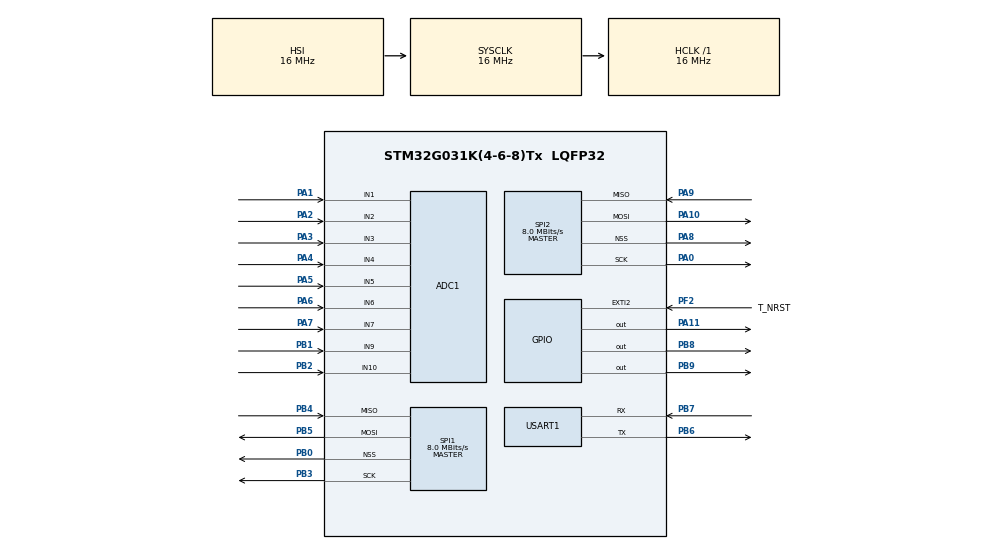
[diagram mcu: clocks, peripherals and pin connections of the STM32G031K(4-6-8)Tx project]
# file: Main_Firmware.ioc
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ADC1.Channel-0\#ChannelRegularConversion=ADC_CHANNEL_4
ADC1.NbrOfConversionFlag=1
ADC1.Rank-0\#ChannelRegularConversion=1
ADC1.SamplingTime-0\#ChannelRegularConversion=ADC_SAMPLINGTIME_COMMON_1
ADC1.SelectedChannel=ADC_CHANNEL_1|ADC_CHANNEL_2|ADC_CHANNEL_3|ADC_CHANNEL_4|ADC_CHANNEL_5|ADC_CHANNEL_6|ADC_CHANNEL_7|ADC_CHANNEL_9|ADC_CHANNEL_10
ADC1.master=1
Mcu.Family=STM32G0
Mcu.Name=STM32G031K(4-6-8)Tx
Mcu.Package=LQFP32
PA0.Mode=Full_Duplex_Master
PA0.Signal=SPI2_SCK
PA1.Mode=IN1
PA1.Signal=ADC1_IN1
PA10.Mode=Full_Duplex_Master
PA10.Signal=SPI2_MOSI
PA11\ [PA9].Signal=GPIO_Output
PA13.GPIO_Label=T_JTMS
PA13.Mode=Serial_Wire
PA13.Signal=SYS_SWDIO
PA14-BOOT0.GPIO_Label=T_JTCK
PA14-BOOT0.Mode=Serial_Wire
PA14-BOOT0.Signal=SYS_SWCLK
PA2.Mode=IN2
PA2.Signal=ADC1_IN2
PA3.Mode=IN3
PA3.Signal=ADC1_IN3
PA4.Mode=IN4
PA4.Signal=ADC1_IN4
PA5.Mode=IN5
PA5.Signal=ADC1_IN5
PA6.Mode=IN6
PA6.Signal=ADC1_IN6
PA7.Mode=IN7
PA7.Signal=ADC1_IN7
PA8.Mode=NSS_Signal_Hard_Output
PA8.Signal=SPI2_NSS
PA9.Mode=Full_Duplex_Master
PA9.Signal=SPI2_MISO
PB0.Mode=NSS_Signal_Hard_Output
PB0.Signal=SPI1_NSS
PB1.Mode=IN9
PB1.Signal=ADC1_IN9
PB2.Mode=IN10
PB2.Signal=ADC1_IN10
PB3.Mode=Full_Duplex_Master
PB3.Signal=SPI1_SCK
PB4.Mode=Full_Duplex_Master
PB4.Signal=SPI1_MISO
PB5.Mode=Full_Duplex_Master
PB5.Signal=SPI1_MOSI
PB6.Mode=Asynchronous
PB6.Signal=USART1_TX
PB7.Mode=Asynchronous
PB7.Signal=USART1_RX
PB8.Signal=GPIO_Output
PB9.Signal=GPIO_Output
PC14-OSC32_IN\ (PC14).Mode=LSE-External-Oscillator
PC14-OSC32_IN\ (PC14).Signal=RCC_OSC32_IN
PC15-OSC32_OUT\ (PC15).Mode=LSE-External-Oscillator
PC15-OSC32_OUT\ (PC15).Signal=RCC_OSC32_OUT
PF2\ -\ NRST.GPIO_Label=T_NRST
PF2\ -\ NRST.Signal=GPXTI2
ProjectManager.HeapSize=0x200
ProjectManager.StackSize=0x400
ProjectManager.TargetToolchain=STM32CubeIDE
RCC.AHBFreq_Value=16000000
RCC.CortexFreq_Value=16000000
RCC.EXTERNAL_CLOCK_VALUE=12288000
RCC.HCLKFreq_Value=16000000
RCC.HSE_VALUE=8000000
RCC.HSI_VALUE=16000000
RCC.SYSCLKFreq_VALUE=16000000
RCC.VCOOutputFreq_Value=128000000
SPI1.CalculateBaudRate=8.0 MBits/s
SPI1.Direction=SPI_DIRECTION_2LINES
SPI1.Mode=SPI_MODE_MASTER
SPI1.VirtualNSS=VM_NSSHARD
SPI1.VirtualType=VM_MASTER
SPI2.CalculateBaudRate=8.0 MBits/s
SPI2.Direction=SPI_DIRECTION_2LINES
SPI2.Mode=SPI_MODE_MASTER
SPI2.VirtualNSS=VM_NSSHARD
SPI2.VirtualType=VM_MASTER
USART1.VirtualMode-Asynchronous=VM_ASYNC
board=NUCLEO-G031K8

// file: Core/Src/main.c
/* USER CODE BEGIN Header */
/**
  ******************************************************************************
  * @file           : main.c
  * @brief          : Main program body
  ******************************************************************************
  * @attention
  *
  * <h2><center>&copy; Copyright (c) 2023 STMicroelectronics.
  * All rights reserved.</center></h2>
  *
  * This software component is licensed by ST under BSD 3-Clause license,
  * the "License"; You may not use this file except in compliance with the
  * License. You may obtain a copy of the License at:
  *                        opensource.org/licenses/BSD-3-Clause
  *
  ******************************************************************************
  */
/* USER CODE END Header */
#include "main.h"
#include "main_loop_controller.h"

ADC_HandleTypeDef hadc1;

SPI_HandleTypeDef hspi1;
SPI_HandleTypeDef hspi2;

UART_HandleTypeDef huart1;

void SystemClock_Config(void);
static void MX_GPIO_Init(void);
static void MX_ADC1_Init(void);
static void MX_SPI2_Init(void);
static void MX_USART1_UART_Init(void);
static void MX_SPI1_Init(void);

int main(void)
{

  /* MCU Configuration--------------------------------------------------------*/

  /* Reset of all peripherals, Initializes the Flash interface and the Systick. */
  HAL_Init();

  /* Configure the system clock */
  SystemClock_Config();

  /* Initialize all configured peripherals */
  MX_GPIO_Init();
  MX_ADC1_Init();
  MX_SPI2_Init();
  MX_USART1_UART_Init();
  MX_SPI1_Init();

  /* USER CODE BEGIN 2 */
  run_once_on_boot();
  /* USER CODE END 2 */

  /* Infinite loop */
  while (1) {
    main_loop();
  }
}

void SystemClock_Config(void)
{
  RCC_OscInitTypeDef RCC_OscInitStruct = {0};
  RCC_ClkInitTypeDef RCC_ClkInitStruct = {0};
  RCC_PeriphCLKInitTypeDef PeriphClkInit = {0};

  /** Configure the main internal regulator output voltage
  */
  HAL_PWREx_ControlVoltageScaling(PWR_REGULATOR_VOLTAGE_SCALE1);
  /** Initializes the RCC Oscillators according to the specified parameters
  * in the RCC_OscInitTypeDef structure.
  */
  RCC_OscInitStruct.OscillatorType = RCC_OSCILLATORTYPE_HSI;
  RCC_OscInitStruct.HSIState = RCC_HSI_ON;
  RCC_OscInitStruct.HSIDiv = RCC_HSI_DIV1;
  RCC_OscInitStruct.HSICalibrationValue = RCC_HSICALIBRATION_DEFAULT;
  RCC_OscInitStruct.PLL.PLLState = RCC_PLL_NONE;
  if (HAL_RCC_OscConfig(&RCC_OscInitStruct) != HAL_OK)
  {
    Error_Handler();
  }
  /** Initializes the CPU, AHB and APB buses clocks
  */
  RCC_ClkInitStruct.ClockType = RCC_CLOCKTYPE_HCLK|RCC_CLOCKTYPE_SYSCLK
                              |RCC_CLOCKTYPE_PCLK1;
  RCC_ClkInitStruct.SYSCLKSource = RCC_SYSCLKSOURCE_HSI;
  RCC_ClkInitStruct.AHBCLKDivider = RCC_SYSCLK_DIV1;
  RCC_ClkInitStruct.APB1CLKDivider = RCC_HCLK_DIV1;

  if (HAL_RCC_ClockConfig(&RCC_ClkInitStruct, FLASH_LATENCY_0) != HAL_OK)
  {
    Error_Handler();
  }
  /** Initializes the peripherals clocks
  */
  PeriphClkInit.PeriphClockSelection = RCC_PERIPHCLK_USART1|RCC_PERIPHCLK_ADC;
  PeriphClkInit.Usart1ClockSelection = RCC_USART1CLKSOURCE_PCLK1;
  PeriphClkInit.AdcClockSelection = RCC_ADCCLKSOURCE_SYSCLK;
  if (HAL_RCCEx_PeriphCLKConfig(&PeriphClkInit) != HAL_OK)
  {
    Error_Handler();
  }
}

static void MX_ADC1_Init(void)
{

  ADC_ChannelConfTypeDef sConfig = {0};

  /** Configure the global features of the ADC (Clock, Resolution, Data Alignment and number of conversion)
  */
  hadc1.Instance = ADC1;
  hadc1.Init.ClockPrescaler = ADC_CLOCK_SYNC_PCLK_DIV2;
  hadc1.Init.Resolution = ADC_RESOLUTION_12B;
  hadc1.Init.DataAlign = ADC_DATAALIGN_RIGHT;
  hadc1.Init.ScanConvMode = ADC_SCAN_DISABLE;
  hadc1.Init.EOCSelection = ADC_EOC_SINGLE_CONV;
  hadc1.Init.LowPowerAutoWait = DISABLE;
  hadc1.Init.LowPowerAutoPowerOff = DISABLE;
  hadc1.Init.ContinuousConvMode = DISABLE;
  hadc1.Init.NbrOfConversion = 1;
  hadc1.Init.DiscontinuousConvMode = DISABLE;
  hadc1.Init.ExternalTrigConv = ADC_SOFTWARE_START;
  hadc1.Init.ExternalTrigConvEdge = ADC_EXTERNALTRIGCONVEDGE_NONE;
  hadc1.Init.DMAContinuousRequests = DISABLE;
  hadc1.Init.Overrun = ADC_OVR_DATA_PRESERVED;
  hadc1.Init.SamplingTimeCommon1 = ADC_SAMPLETIME_1CYCLE_5;
  hadc1.Init.SamplingTimeCommon2 = ADC_SAMPLETIME_1CYCLE_5;
  hadc1.Init.OversamplingMode = DISABLE;
  hadc1.Init.TriggerFrequencyMode = ADC_TRIGGER_FREQ_HIGH;
  if (HAL_ADC_Init(&hadc1) != HAL_OK)
  {
    Error_Handler();
  }
  /** Configure Regular Channel
  */
  sConfig.Channel = ADC_CHANNEL_4;
  sConfig.Rank = ADC_REGULAR_RANK_1;
  sConfig.SamplingTime = ADC_SAMPLINGTIME_COMMON_1;
  if (HAL_ADC_ConfigChannel(&hadc1, &sConfig) != HAL_OK)
  {
    Error_Handler();
  }

}

static void MX_SPI1_Init(void)
{

  /* SPI1 parameter configuration*/
  hspi1.Instance = SPI1;
  hspi1.Init.Mode = SPI_MODE_MASTER;
  hspi1.Init.Direction = SPI_DIRECTION_2LINES;
  hspi1.Init.DataSize = SPI_DATASIZE_8BIT;
  hspi1.Init.CLKPolarity = SPI_POLARITY_LOW;
  hspi1.Init.CLKPhase = SPI_PHASE_1EDGE;
  hspi1.Init.NSS = SPI_NSS_HARD_OUTPUT;
  hspi1.Init.BaudRatePrescaler = SPI_BAUDRATEPRESCALER_2;
  hspi1.Init.FirstBit = SPI_FIRSTBIT_MSB;
  hspi1.Init.TIMode = SPI_TIMODE_DISABLE;
  hspi1.Init.CRCCalculation = SPI_CRCCALCULATION_DISABLE;
  hspi1.Init.CRCPolynomial = 7;
  hspi1.Init.CRCLength = SPI_CRC_LENGTH_DATASIZE;
  hspi1.Init.NSSPMode = SPI_NSS_PULSE_ENABLE;
  if (HAL_SPI_Init(&hspi1) != HAL_OK)
  {
    Error_Handler();
  }

}

static void MX_SPI2_Init(void)
{

  /* SPI2 parameter configuration*/
  hspi2.Instance = SPI2;
  hspi2.Init.Mode = SPI_MODE_MASTER;
  hspi2.Init.Direction = SPI_DIRECTION_2LINES;
  hspi2.Init.DataSize = SPI_DATASIZE_8BIT;
  hspi2.Init.CLKPolarity = SPI_POLARITY_LOW;
  hspi2.Init.CLKPhase = SPI_PHASE_1EDGE;
  hspi2.Init.NSS = SPI_NSS_HARD_OUTPUT;
  hspi2.Init.BaudRatePrescaler = SPI_BAUDRATEPRESCALER_2;
  hspi2.Init.FirstBit = SPI_FIRSTBIT_MSB;
  hspi2.Init.TIMode = SPI_TIMODE_DISABLE;
  hspi2.Init.CRCCalculation = SPI_CRCCALCULATION_DISABLE;
  hspi2.Init.CRCPolynomial = 7;
  hspi2.Init.CRCLength = SPI_CRC_LENGTH_DATASIZE;
  hspi2.Init.NSSPMode = SPI_NSS_PULSE_ENABLE;
  if (HAL_SPI_Init(&hspi2) != HAL_OK)
  {
    Error_Handler();
  }

}

static void MX_USART1_UART_Init(void)
{

  huart1.Instance = USART1;
  huart1.Init.BaudRate = 115200;
  huart1.Init.WordLength = UART_WORDLENGTH_8B;
  huart1.Init.StopBits = UART_STOPBITS_1;
  huart1.Init.Parity = UART_PARITY_NONE;
  huart1.Init.Mode = UART_MODE_TX_RX;
  huart1.Init.HwFlowCtl = UART_HWCONTROL_NONE;
  huart1.Init.OverSampling = UART_OVERSAMPLING_16;
  huart1.Init.OneBitSampling = UART_ONE_BIT_SAMPLE_DISABLE;
  huart1.Init.ClockPrescaler = UART_PRESCALER_DIV1;
  huart1.AdvancedInit.AdvFeatureInit = UART_ADVFEATURE_NO_INIT;
  if (HAL_UART_Init(&huart1) != HAL_OK)
  {
    Error_Handler();
  }
  if (HAL_UARTEx_SetTxFifoThreshold(&huart1, UART_TXFIFO_THRESHOLD_1_8) != HAL_OK)
  {
    Error_Handler();
  }
  if (HAL_UARTEx_SetRxFifoThreshold(&huart1, UART_RXFIFO_THRESHOLD_1_8) != HAL_OK)
  {
    Error_Handler();
  }
  if (HAL_UARTEx_DisableFifoMode(&huart1) != HAL_OK)
  {
    Error_Handler();
  }

}

static void MX_GPIO_Init(void)
{
  GPIO_InitTypeDef GPIO_InitStruct = {0};

  /* GPIO Ports Clock Enable */
  __HAL_RCC_GPIOB_CLK_ENABLE();
  __HAL_RCC_GPIOC_CLK_ENABLE();
  __HAL_RCC_GPIOF_CLK_ENABLE();
  __HAL_RCC_GPIOA_CLK_ENABLE();

  /*Configure GPIO pin Output Level */
  HAL_GPIO_WritePin(GPIOB, GPIO_PIN_9|GPIO_PIN_8, GPIO_PIN_RESET);

  /*Configure GPIO pin Output Level */
  HAL_GPIO_WritePin(GPIOA, GPIO_PIN_11, GPIO_PIN_RESET);

  /*Configure GPIO pins : PB9 PB8 */
  GPIO_InitStruct.Pin = GPIO_PIN_9|GPIO_PIN_8;
  GPIO_InitStruct.Mode = GPIO_MODE_OUTPUT_PP;
  GPIO_InitStruct.Pull = GPIO_NOPULL;
  GPIO_InitStruct.Speed = GPIO_SPEED_FREQ_LOW;
  HAL_GPIO_Init(GPIOB, &GPIO_InitStruct);

  /*Configure GPIO pin : T_NRST_Pin */
  GPIO_InitStruct.Pin = T_NRST_Pin;
  GPIO_InitStruct.Mode = GPIO_MODE_IT_RISING;
  GPIO_InitStruct.Pull = GPIO_NOPULL;
  HAL_GPIO_Init(T_NRST_GPIO_Port, &GPIO_InitStruct);

  /*Configure GPIO pin : PA11 */
  GPIO_InitStruct.Pin = GPIO_PIN_11;
  GPIO_InitStruct.Mode = GPIO_MODE_OUTPUT_PP;
  GPIO_InitStruct.Pull = GPIO_NOPULL;
  GPIO_InitStruct.Speed = GPIO_SPEED_FREQ_LOW;
  HAL_GPIO_Init(GPIOA, &GPIO_InitStruct);

}

void Error_Handler(void)
{
  __disable_irq();
  while (1)
  {
  }
}

/************************ (C) COPYRIGHT STMicroelectronics *****END OF FILE****/
